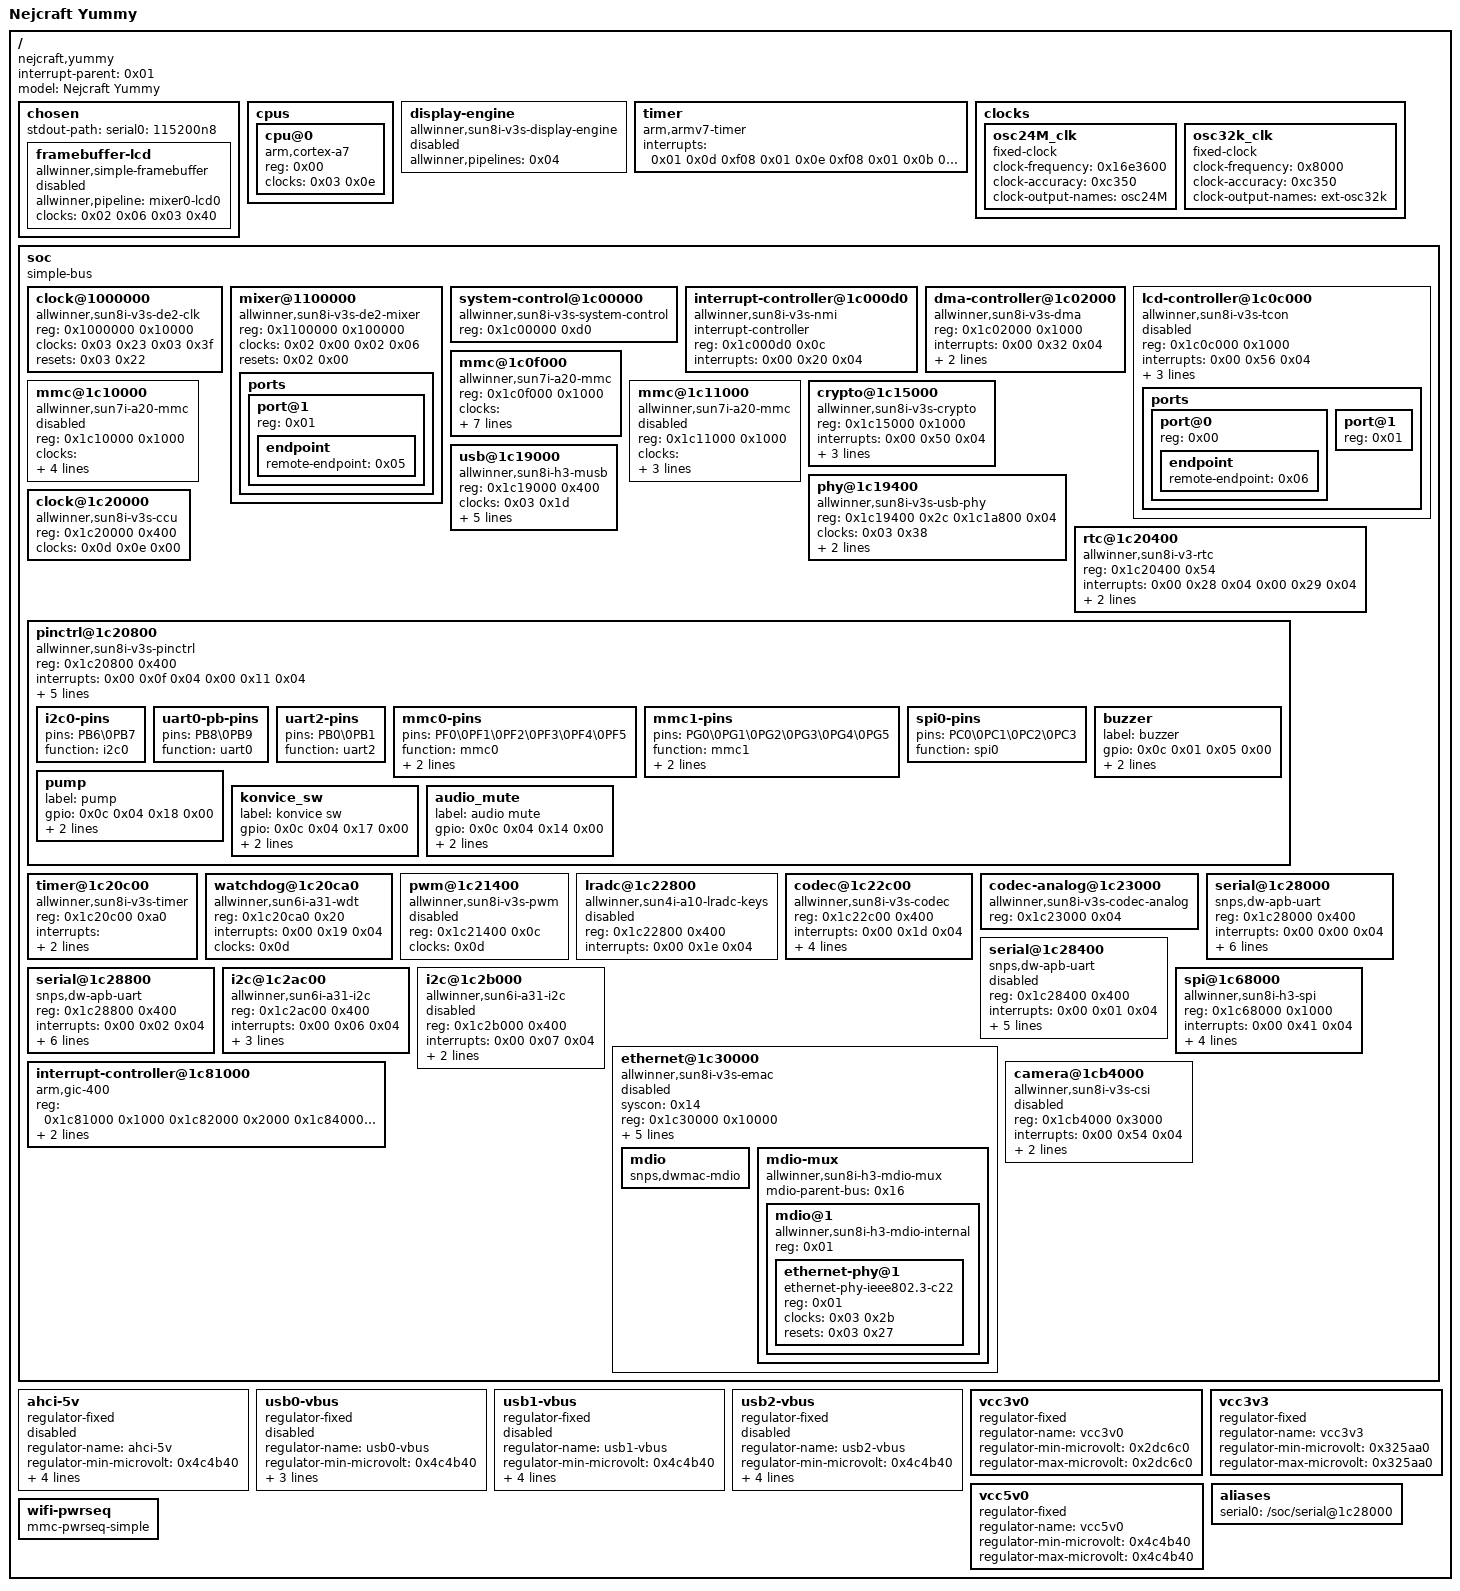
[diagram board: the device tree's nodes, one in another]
/dts-v1/;

/ {
	#address-cells = <0x01>;
	#size-cells = <0x01>;
	interrupt-parent = <0x01>;
	model = "Nejcraft Yummy";
	compatible = "nejcraft,yummy\0allwinner,sun8i-v3s";

	chosen {
		#address-cells = <0x01>;
		#size-cells = <0x01>;
		ranges;
		stdout-path = "serial0: 115200n8";

		framebuffer-lcd {
			compatible = "allwinner,simple-framebuffer\0simple-framebuffer";
			allwinner,pipeline = "mixer0-lcd0";
			clocks = <0x02 0x06 0x03 0x40>;
			status = "disabled";
		};
	};

	cpus {
		#address-cells = <0x01>;
		#size-cells = <0x00>;

		cpu@0 {
			compatible = "arm,cortex-a7";
			device_type = "cpu";
			reg = <0x00>;
			clocks = <0x03 0x0e>;
		};
	};

	display-engine {
		compatible = "allwinner,sun8i-v3s-display-engine";
		allwinner,pipelines = <0x04>;
		status = "disabled";
	};

	timer {
		compatible = "arm,armv7-timer";
		interrupts = <0x01 0x0d 0xf08 0x01 0x0e 0xf08 0x01 0x0b 0xf08 0x01 0x0a 0xf08>;
	};

	clocks {
		#address-cells = <0x01>;
		#size-cells = <0x01>;
		ranges;

		osc24M_clk {
			#clock-cells = <0x00>;
			compatible = "fixed-clock";
			clock-frequency = <0x16e3600>;
			clock-accuracy = <0xc350>;
			clock-output-names = "osc24M";
			phandle = <0x0d>;
		};

		osc32k_clk {
			#clock-cells = <0x00>;
			compatible = "fixed-clock";
			clock-frequency = <0x8000>;
			clock-accuracy = <0xc350>;
			clock-output-names = "ext-osc32k";
			phandle = <0x0f>;
		};
	};

	soc {
		compatible = "simple-bus";
		#address-cells = <0x01>;
		#size-cells = <0x01>;
		ranges;

		clock@1000000 {
			compatible = "allwinner,sun8i-v3s-de2-clk";
			reg = <0x1000000 0x10000>;
			clocks = <0x03 0x23 0x03 0x3f>;
			clock-names = "bus\0mod";
			resets = <0x03 0x22>;
			#clock-cells = <0x01>;
			#reset-cells = <0x01>;
			phandle = <0x02>;
		};

		mixer@1100000 {
			compatible = "allwinner,sun8i-v3s-de2-mixer";
			reg = <0x1100000 0x100000>;
			clocks = <0x02 0x00 0x02 0x06>;
			clock-names = "bus\0mod";
			resets = <0x02 0x00>;
			phandle = <0x04>;

			ports {
				#address-cells = <0x01>;
				#size-cells = <0x00>;

				port@1 {
					reg = <0x01>;

					endpoint {
						remote-endpoint = <0x05>;
						phandle = <0x06>;
					};
				};
			};
		};

		system-control@1c00000 {
			compatible = "allwinner,sun8i-v3s-system-control\0allwinner,sun8i-h3-system-control";
			reg = <0x1c00000 0xd0>;
			#address-cells = <0x01>;
			#size-cells = <0x01>;
			ranges;
			phandle = <0x14>;
		};

		interrupt-controller@1c000d0 {
			compatible = "allwinner,sun8i-v3s-nmi\0allwinner,sun9i-a80-nmi";
			interrupt-controller;
			#interrupt-cells = <0x02>;
			reg = <0x1c000d0 0x0c>;
			interrupts = <0x00 0x20 0x04>;
		};

		dma-controller@1c02000 {
			compatible = "allwinner,sun8i-v3s-dma";
			reg = <0x1c02000 0x1000>;
			interrupts = <0x00 0x32 0x04>;
			clocks = <0x03 0x15>;
			resets = <0x03 0x06>;
			#dma-cells = <0x01>;
			phandle = <0x0a>;
		};

		lcd-controller@1c0c000 {
			compatible = "allwinner,sun8i-v3s-tcon";
			reg = <0x1c0c000 0x1000>;
			interrupts = <0x00 0x56 0x04>;
			clocks = <0x03 0x21 0x03 0x40>;
			clock-names = "ahb\0tcon-ch0";
			clock-output-names = "tcon-pixel-clock";
			#clock-cells = <0x00>;
			resets = <0x03 0x1b>;
			reset-names = "lcd";
			status = "disabled";

			ports {
				#address-cells = <0x01>;
				#size-cells = <0x00>;

				port@0 {
					reg = <0x00>;

					endpoint {
						remote-endpoint = <0x06>;
						phandle = <0x05>;
					};
				};

				port@1 {
					#address-cells = <0x01>;
					#size-cells = <0x00>;
					reg = <0x01>;
				};
			};
		};

		mmc@1c0f000 {
			compatible = "allwinner,sun7i-a20-mmc";
			reg = <0x1c0f000 0x1000>;
			clocks = <0x03 0x16 0x03 0x2d 0x03 0x2f 0x03 0x2e>;
			clock-names = "ahb\0mmc\0output\0sample";
			resets = <0x03 0x07>;
			reset-names = "ahb";
			interrupts = <0x00 0x3c 0x04>;
			pinctrl-names = "default";
			pinctrl-0 = <0x07>;
			status = "okay";
			#address-cells = <0x01>;
			#size-cells = <0x00>;
			broken-cd;
			bus-width = <0x04>;
			vmmc-supply = <0x08>;
		};

		mmc@1c10000 {
			compatible = "allwinner,sun7i-a20-mmc";
			reg = <0x1c10000 0x1000>;
			clocks = <0x03 0x17 0x03 0x30 0x03 0x32 0x03 0x31>;
			clock-names = "ahb\0mmc\0output\0sample";
			resets = <0x03 0x08>;
			reset-names = "ahb";
			interrupts = <0x00 0x3d 0x04>;
			pinctrl-names = "default";
			pinctrl-0 = <0x09>;
			status = "disabled";
			#address-cells = <0x01>;
			#size-cells = <0x00>;
		};

		mmc@1c11000 {
			compatible = "allwinner,sun7i-a20-mmc";
			reg = <0x1c11000 0x1000>;
			clocks = <0x03 0x18 0x03 0x33 0x03 0x35 0x03 0x34>;
			clock-names = "ahb\0mmc\0output\0sample";
			resets = <0x03 0x09>;
			reset-names = "ahb";
			interrupts = <0x00 0x3e 0x04>;
			status = "disabled";
			#address-cells = <0x01>;
			#size-cells = <0x00>;
		};

		crypto@1c15000 {
			compatible = "allwinner,sun8i-v3s-crypto\0allwinner,sun8i-a33-crypto";
			reg = <0x1c15000 0x1000>;
			interrupts = <0x00 0x50 0x04>;
			clocks = <0x03 0x14 0x03 0x36>;
			clock-names = "ahb\0mod";
			dmas = <0x0a 0x10 0x0a 0x10>;
			dma-names = "rx\0tx";
			resets = <0x03 0x05>;
			reset-names = "ahb";
		};

		usb@1c19000 {
			compatible = "allwinner,sun8i-h3-musb";
			reg = <0x1c19000 0x400>;
			clocks = <0x03 0x1d>;
			resets = <0x03 0x11>;
			interrupts = <0x00 0x47 0x04>;
			interrupt-names = "mc";
			phys = <0x0b 0x00>;
			phy-names = "usb";
			extcon = <0x0b 0x00>;
			status = "okay";
			dr_mode = "otg";
		};

		phy@1c19400 {
			compatible = "allwinner,sun8i-v3s-usb-phy";
			reg = <0x1c19400 0x2c 0x1c1a800 0x04>;
			reg-names = "phy_ctrl\0pmu0";
			clocks = <0x03 0x38>;
			clock-names = "usb0_phy";
			resets = <0x03 0x00>;
			reset-names = "usb0_reset";
			status = "okay";
			#phy-cells = <0x01>;
			usb0_id_det-gpios = <0x0c 0x05 0x06 0x00>;
			phandle = <0x0b>;
		};

		clock@1c20000 {
			compatible = "allwinner,sun8i-v3s-ccu";
			reg = <0x1c20000 0x400>;
			clocks = <0x0d 0x0e 0x00>;
			clock-names = "hosc\0losc";
			#clock-cells = <0x01>;
			#reset-cells = <0x01>;
			phandle = <0x03>;
		};

		rtc@1c20400 {
			#clock-cells = <0x01>;
			compatible = "allwinner,sun8i-v3-rtc";
			reg = <0x1c20400 0x54>;
			interrupts = <0x00 0x28 0x04 0x00 0x29 0x04>;
			clocks = <0x0f>;
			clock-output-names = "osc32k\0osc32k-out";
			phandle = <0x0e>;
		};

		pinctrl@1c20800 {
			compatible = "allwinner,sun8i-v3s-pinctrl";
			reg = <0x1c20800 0x400>;
			interrupts = <0x00 0x0f 0x04 0x00 0x11 0x04>;
			clocks = <0x03 0x25 0x0d 0x0e 0x00>;
			clock-names = "apb\0hosc\0losc";
			gpio-controller;
			#gpio-cells = <0x03>;
			interrupt-controller;
			#interrupt-cells = <0x03>;
			gpio-line-names = [00 00 00 00 00 00 00 00 00 00 00 00 00 00 00 00 00 00 00 00 00 00 00 00 00 00 00 00 00 00 00 00 50 42 30 00 50 42 31 00 50 42 32 00 50 42 33 00 50 42 34 00 50 42 35 00 50 42 36 00 50 42 37 00 50 42 38 00 00 00 00 00 00 00 00 00 00 00 00 00 00 00 00 00 00 00 00 00 00 00 00 00 50 43 30 00 50 43 31 00 50 43 32 00 50 43 33 00 00 00 00 00 00 00 00 00 00 00 00 00 00 00 00 00 00 00 00 00 00 00 00 00 00 00 00 00 00 00 00 00 00 00 00 00 00 00 00 00 00 00 00 00 00 00 00 00 00 00 00 00 00 00 00 00 00 00 00 00 50 45 30 00 50 45 31 00 50 45 32 00 50 45 33 00 50 45 34 00 50 45 35 00 50 45 36 00 50 45 37 00 50 45 38 00 50 45 39 00 50 45 31 30 00 50 45 31 31 00 50 45 31 32 00 50 45 31 33 00 50 45 31 34 00 50 45 31 35 00 50 45 31 36 00 50 45 31 37 00 50 45 31 38 00 50 45 31 39 00 50 45 32 30 00 50 45 32 31 00 50 45 32 32 00 50 45 32 33 00 50 45 32 34 00 00 00 00 00 00 00 00 00 50 46 30 00 50 46 31 00 50 46 32 00 50 46 33 00 50 46 34 00 50 46 35 00 50 46 36 00 00 00 00 00 00 00 00 00 00 00 00 00 00 00 00 00 00 00 00 00 00 00 00 00 00 50 47 30 00 50 47 31 00 50 47 32 00 50 47 33 00 50 47 34 00 50 47 35 00 00 00 00 00 00 00 00 00 00 00 00 00 00 00 00 00 00 00 00 00 00 00 00 00 00 00];
			phandle = <0x0c>;

			i2c0-pins {
				pins = "PB6\0PB7";
				function = "i2c0";
				phandle = <0x13>;
			};

			uart0-pb-pins {
				pins = "PB8\0PB9";
				function = "uart0";
				phandle = <0x11>;
			};

			uart2-pins {
				pins = "PB0\0PB1";
				function = "uart2";
				phandle = <0x12>;
			};

			mmc0-pins {
				pins = "PF0\0PF1\0PF2\0PF3\0PF4\0PF5";
				function = "mmc0";
				drive-strength = <0x1e>;
				bias-pull-up;
				phandle = <0x07>;
			};

			mmc1-pins {
				pins = "PG0\0PG1\0PG2\0PG3\0PG4\0PG5";
				function = "mmc1";
				drive-strength = <0x1e>;
				bias-pull-up;
				phandle = <0x09>;
			};

			spi0-pins {
				pins = "PC0\0PC1\0PC2\0PC3";
				function = "spi0";
				phandle = <0x17>;
			};

			buzzer {
				label = "buzzer";
				gpio = <0x0c 0x01 0x05 0x00>;
				output;
				init-low;
			};

			pump {
				label = "pump";
				gpio = <0x0c 0x04 0x18 0x00>;
				output;
				init-low;
			};

			konvice_sw {
				label = "konvice sw";
				gpio = <0x0c 0x04 0x17 0x00>;
				output;
				init-low;
			};

			audio_mute {
				label = "audio mute";
				gpio = <0x0c 0x04 0x14 0x00>;
				output;
				init-low;
			};
		};

		timer@1c20c00 {
			compatible = "allwinner,sun8i-v3s-timer";
			reg = <0x1c20c00 0xa0>;
			interrupts = <0x00 0x12 0x04 0x00 0x13 0x04 0x00 0x14 0x04>;
			clocks = <0x0d>;
		};

		watchdog@1c20ca0 {
			compatible = "allwinner,sun6i-a31-wdt";
			reg = <0x1c20ca0 0x20>;
			interrupts = <0x00 0x19 0x04>;
			clocks = <0x0d>;
		};

		pwm@1c21400 {
			compatible = "allwinner,sun8i-v3s-pwm\0allwinner,sun7i-a20-pwm";
			reg = <0x1c21400 0x0c>;
			clocks = <0x0d>;
			#pwm-cells = <0x03>;
			status = "disabled";
		};

		lradc@1c22800 {
			compatible = "allwinner,sun4i-a10-lradc-keys";
			reg = <0x1c22800 0x400>;
			interrupts = <0x00 0x1e 0x04>;
			status = "disabled";
		};

		codec@1c22c00 {
			#sound-dai-cells = <0x00>;
			compatible = "allwinner,sun8i-v3s-codec";
			reg = <0x1c22c00 0x400>;
			interrupts = <0x00 0x1d 0x04>;
			clocks = <0x03 0x24 0x03 0x46>;
			clock-names = "apb\0codec";
			resets = <0x03 0x28>;
			dmas = <0x0a 0x0f 0x0a 0x0f>;
			dma-names = "rx\0tx";
			allwinner,codec-analog-controls = <0x10>;
			status = "okay";
		};

		codec-analog@1c23000 {
			compatible = "allwinner,sun8i-v3s-codec-analog";
			reg = <0x1c23000 0x04>;
			phandle = <0x10>;
		};

		serial@1c28000 {
			compatible = "snps,dw-apb-uart";
			reg = <0x1c28000 0x400>;
			interrupts = <0x00 0x00 0x04>;
			reg-shift = <0x02>;
			reg-io-width = <0x04>;
			clocks = <0x03 0x28>;
			dmas = <0x0a 0x06 0x0a 0x06>;
			dma-names = "rx\0tx";
			resets = <0x03 0x31>;
			status = "okay";
			pinctrl-0 = <0x11>;
			pinctrl-names = "default";
		};

		serial@1c28400 {
			compatible = "snps,dw-apb-uart";
			reg = <0x1c28400 0x400>;
			interrupts = <0x00 0x01 0x04>;
			reg-shift = <0x02>;
			reg-io-width = <0x04>;
			clocks = <0x03 0x29>;
			dmas = <0x0a 0x07 0x0a 0x07>;
			dma-names = "rx\0tx";
			resets = <0x03 0x32>;
			status = "disabled";
		};

		serial@1c28800 {
			compatible = "snps,dw-apb-uart";
			reg = <0x1c28800 0x400>;
			interrupts = <0x00 0x02 0x04>;
			reg-shift = <0x02>;
			reg-io-width = <0x04>;
			clocks = <0x03 0x2a>;
			dmas = <0x0a 0x08 0x0a 0x08>;
			dma-names = "rx\0tx";
			resets = <0x03 0x33>;
			pinctrl-0 = <0x12>;
			pinctrl-names = "default";
			status = "okay";
		};

		i2c@1c2ac00 {
			compatible = "allwinner,sun6i-a31-i2c";
			reg = <0x1c2ac00 0x400>;
			interrupts = <0x00 0x06 0x04>;
			clocks = <0x03 0x26>;
			resets = <0x03 0x2e>;
			pinctrl-names = "default";
			pinctrl-0 = <0x13>;
			status = "okay";
			#address-cells = <0x01>;
			#size-cells = <0x00>;
		};

		i2c@1c2b000 {
			compatible = "allwinner,sun6i-a31-i2c";
			reg = <0x1c2b000 0x400>;
			interrupts = <0x00 0x07 0x04>;
			clocks = <0x03 0x27>;
			resets = <0x03 0x2f>;
			status = "disabled";
			#address-cells = <0x01>;
			#size-cells = <0x00>;
		};

		ethernet@1c30000 {
			compatible = "allwinner,sun8i-v3s-emac";
			syscon = <0x14>;
			reg = <0x1c30000 0x10000>;
			interrupts = <0x00 0x52 0x04>;
			interrupt-names = "macirq";
			resets = <0x03 0x0c>;
			reset-names = "stmmaceth";
			clocks = <0x03 0x1a>;
			clock-names = "stmmaceth";
			phy-handle = <0x15>;
			phy-mode = "mii";
			status = "disabled";

			mdio {
				#address-cells = <0x01>;
				#size-cells = <0x00>;
				compatible = "snps,dwmac-mdio";
				phandle = <0x16>;
			};

			mdio-mux {
				compatible = "allwinner,sun8i-h3-mdio-mux";
				#address-cells = <0x01>;
				#size-cells = <0x00>;
				mdio-parent-bus = <0x16>;

				mdio@1 {
					compatible = "allwinner,sun8i-h3-mdio-internal";
					reg = <0x01>;
					#address-cells = <0x01>;
					#size-cells = <0x00>;

					ethernet-phy@1 {
						compatible = "ethernet-phy-ieee802.3-c22";
						reg = <0x01>;
						clocks = <0x03 0x2b>;
						resets = <0x03 0x27>;
						phandle = <0x15>;
					};
				};
			};
		};

		spi@1c68000 {
			compatible = "allwinner,sun8i-h3-spi";
			reg = <0x1c68000 0x1000>;
			interrupts = <0x00 0x41 0x04>;
			clocks = <0x03 0x1c 0x03 0x37>;
			clock-names = "ahb\0mod";
			dmas = <0x0a 0x17 0x0a 0x17>;
			dma-names = "rx\0tx";
			pinctrl-names = "default";
			pinctrl-0 = <0x17>;
			resets = <0x03 0x0f>;
			status = "okay";
			#address-cells = <0x01>;
			#size-cells = <0x00>;
		};

		interrupt-controller@1c81000 {
			compatible = "arm,gic-400";
			reg = <0x1c81000 0x1000 0x1c82000 0x2000 0x1c84000 0x2000 0x1c86000 0x2000>;
			interrupt-controller;
			#interrupt-cells = <0x03>;
			interrupts = <0x01 0x09 0xf04>;
			phandle = <0x01>;
		};

		camera@1cb4000 {
			compatible = "allwinner,sun8i-v3s-csi";
			reg = <0x1cb4000 0x3000>;
			interrupts = <0x00 0x54 0x04>;
			clocks = <0x03 0x22 0x03 0x43 0x03 0x3c>;
			clock-names = "bus\0mod\0ram";
			resets = <0x03 0x1e>;
			status = "disabled";
		};
	};

	ahci-5v {
		compatible = "regulator-fixed";
		regulator-name = "ahci-5v";
		regulator-min-microvolt = <0x4c4b40>;
		regulator-max-microvolt = <0x4c4b40>;
		regulator-boot-on;
		enable-active-high;
		gpio = <0x0c 0x01 0x08 0x00>;
		status = "disabled";
	};

	usb0-vbus {
		compatible = "regulator-fixed";
		regulator-name = "usb0-vbus";
		regulator-min-microvolt = <0x4c4b40>;
		regulator-max-microvolt = <0x4c4b40>;
		enable-active-high;
		gpio = <0x0c 0x01 0x09 0x00>;
		status = "disabled";
	};

	usb1-vbus {
		compatible = "regulator-fixed";
		regulator-name = "usb1-vbus";
		regulator-min-microvolt = <0x4c4b40>;
		regulator-max-microvolt = <0x4c4b40>;
		regulator-boot-on;
		enable-active-high;
		gpio = <0x0c 0x07 0x06 0x00>;
		status = "disabled";
	};

	usb2-vbus {
		compatible = "regulator-fixed";
		regulator-name = "usb2-vbus";
		regulator-min-microvolt = <0x4c4b40>;
		regulator-max-microvolt = <0x4c4b40>;
		regulator-boot-on;
		enable-active-high;
		gpio = <0x0c 0x07 0x03 0x00>;
		status = "disabled";
	};

	vcc3v0 {
		compatible = "regulator-fixed";
		regulator-name = "vcc3v0";
		regulator-min-microvolt = <0x2dc6c0>;
		regulator-max-microvolt = <0x2dc6c0>;
	};

	vcc3v3 {
		compatible = "regulator-fixed";
		regulator-name = "vcc3v3";
		regulator-min-microvolt = <0x325aa0>;
		regulator-max-microvolt = <0x325aa0>;
		phandle = <0x08>;
	};

	vcc5v0 {
		compatible = "regulator-fixed";
		regulator-name = "vcc5v0";
		regulator-min-microvolt = <0x4c4b40>;
		regulator-max-microvolt = <0x4c4b40>;
	};

	aliases {
		serial0 = "/soc/serial@1c28000";
	};

	wifi-pwrseq {
		compatible = "mmc-pwrseq-simple";
	};
};
